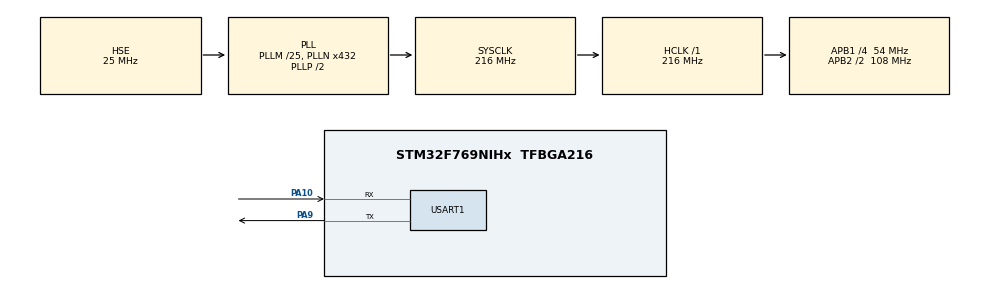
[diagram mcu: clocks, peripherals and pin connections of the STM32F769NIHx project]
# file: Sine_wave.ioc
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CORTEX_M7.ART_ACCELERATOR_ENABLE=0
CORTEX_M7.CPU_DCache=Enabled
CORTEX_M7.CPU_ICache=Enabled
Mcu.Family=STM32F7
Mcu.Name=STM32F769NIHx
Mcu.Package=TFBGA216
NVIC.PriorityGroup=NVIC_PRIORITYGROUP_4
PA10.Mode=Asynchronous
PA10.Signal=USART1_RX
PA13.Mode=Serial_Wire
PA13.Signal=SYS_JTMS-SWDIO
PA14.Mode=Serial_Wire
PA14.Signal=SYS_JTCK-SWCLK
PA9.Mode=Asynchronous
PA9.Signal=USART1_TX
PC14/OSC32_IN.Mode=LSE-External-Oscillator
PC14/OSC32_IN.Signal=RCC_OSC32_IN
PC15/OSC32_OUT.Mode=LSE-External-Oscillator
PC15/OSC32_OUT.Signal=RCC_OSC32_OUT
PH0/OSC_IN.Mode=HSE-External-Oscillator
PH0/OSC_IN.Signal=RCC_OSC_IN
PH1/OSC_OUT.Mode=HSE-External-Oscillator
PH1/OSC_OUT.Signal=RCC_OSC_OUT
ProjectManager.HeapSize=0x800
ProjectManager.StackSize=0x800
ProjectManager.TargetToolchain=STM32CubeIDE
RCC.AHBFreq_Value=216000000
RCC.APB1CLKDivider=RCC_HCLK_DIV4
RCC.APB1Freq_Value=54000000
RCC.APB1TimFreq_Value=108000000
RCC.APB2CLKDivider=RCC_HCLK_DIV2
RCC.APB2Freq_Value=108000000
RCC.APB2TimFreq_Value=216000000
RCC.CortexFreq_Value=216000000
RCC.HCLKFreq_Value=216000000
RCC.HSE_VALUE=25000000
RCC.HSI_VALUE=16000000
RCC.PLLM=25
RCC.PLLN=432
RCC.PLLQ=4
RCC.PLLSAIQ=3
RCC.PLLSourceVirtual=RCC_PLLSOURCE_HSE
RCC.SYSCLKFreq_VALUE=216000000
RCC.SYSCLKSource=RCC_SYSCLKSOURCE_PLLCLK
RCC.USBFreq_Value=108000000
RCC.VCOOutputFreq_Value=432000000
STMicroelectronics.X-CUBE-AI.9.0.0.ActivationBufferSizeList=128
STMicroelectronics.X-CUBE-AI.9.0.0.ActivationBuffers=pool0
STMicroelectronics.X-CUBE-AI.9.0.0.ActivationNames=pool0
STMicroelectronics.X-CUBE-AI.9.0.0.ActivationSizes=AI_SIN_WAVE_DATA_ACTIVATION_1_SIZE
STMicroelectronics.X-CUBE-AI.9.0.0.HeapSize=0x800
STMicroelectronics.X-CUBE-AI.9.0.0.InternalRamActivationBufferMaxSize=AI_SIN_WAVE_DATA_ACTIVATIONS_SIZE
STMicroelectronics.X-CUBE-AI.9.0.0.LatestDirectoryUsed-826814ab56f44155a73fceece242ecaec9d7efd1946fa1af281f79f9bccddd98=E\:\\AI_Workspace\\Machine_learning_Study
STMicroelectronics.X-CUBE-AI.9.0.0.MaximumNumberOfInputLayer=1
STMicroelectronics.X-CUBE-AI.9.0.0.MaximumNumberOfOutputLayer=1
STMicroelectronics.X-CUBE-AI.9.0.0.MaximumSizeOfInputLayer=1
STMicroelectronics.X-CUBE-AI.9.0.0.MaximumSizeOfOutputLayer=1
STMicroelectronics.X-CUBE-AI.9.0.0.ModelActualCompression-826814ab56f44155a73fceece242ecaec9d7efd1946fa1af281f79f9bccddd98=0.0
STMicroelectronics.X-CUBE-AI.9.0.0.ModelCompression-826814ab56f44155a73fceece242ecaec9d7efd1946fa1af281f79f9bccddd98=None
STMicroelectronics.X-CUBE-AI.9.0.0.ModelFlashOccupation-826814ab56f44155a73fceece242ecaec9d7efd1946fa1af281f79f9bccddd98=1284
STMicroelectronics.X-CUBE-AI.9.0.0.ModelHashList=826814ab56f44155a73fceece242ecaec9d7efd1946fa1af281f79f9bccddd98
STMicroelectronics.X-CUBE-AI.9.0.0.ModelKind-826814ab56f44155a73fceece242ecaec9d7efd1946fa1af281f79f9bccddd98=TFLITE
STMicroelectronics.X-CUBE-AI.9.0.0.ModelMacc-826814ab56f44155a73fceece242ecaec9d7efd1946fa1af281f79f9bccddd98=353
STMicroelectronics.X-CUBE-AI.9.0.0.ModelName-826814ab56f44155a73fceece242ecaec9d7efd1946fa1af281f79f9bccddd98=sin_wave
STMicroelectronics.X-CUBE-AI.9.0.0.ModelNameList=sin_wave
STMicroelectronics.X-CUBE-AI.9.0.0.ModelRamOccupation-826814ab56f44155a73fceece242ecaec9d7efd1946fa1af281f79f9bccddd98=128
STMicroelectronics.X-CUBE-AI.9.0.0.ModelStructureFile-826814ab56f44155a73fceece242ecaec9d7efd1946fa1af281f79f9bccddd98=E\:\\AI_Workspace\\Machine_learning_Study\\sine_model.tflite
STMicroelectronics.X-CUBE-AI.9.0.0.ModelType-826814ab56f44155a73fceece242ecaec9d7efd1946fa1af281f79f9bccddd98=STM32Cube.AI MCU runtime
STMicroelectronics.X-CUBE-AI.9.0.0.ReadyForCodeGeneration=true
STMicroelectronics.X-CUBE-AI.9.0.0.StackSize=0x800
STMicroelectronics.X-CUBE-AI.9.0.0.WorkingBufferStartAddrList=0xFFFFFFFF
STMicroelectronics.X-CUBE-AI.9.0.0.XAaCUBEAaAICcArtificialOoIntelligenceJjCore=true
STMicroelectronics.X-CUBE-AI.9.0.0.copyWeightToRam=false
STMicroelectronics.X-CUBE-AI.9.0.0.copyWeightToRam-826814ab56f44155a73fceece242ecaec9d7efd1946fa1af281f79f9bccddd98=false
STMicroelectronics.X-CUBE-AI.9.0.0.customLayerConfigEnabled=false
STMicroelectronics.X-CUBE-AI.9.0.0.customLayerConfigEnabled-826814ab56f44155a73fceece242ecaec9d7efd1946fa1af281f79f9bccddd98=false
STMicroelectronics.X-CUBE-AI.9.0.0.noOnnxIoTranspose=false
STMicroelectronics.X-CUBE-AI.9.0.0.noOnnxIoTranspose-826814ab56f44155a73fceece242ecaec9d7efd1946fa1af281f79f9bccddd98=false
STMicroelectronics.X-CUBE-AI.9.0.0.useInputAllocation=true
STMicroelectronics.X-CUBE-AI.9.0.0.useInputAllocation-826814ab56f44155a73fceece242ecaec9d7efd1946fa1af281f79f9bccddd98=true
STMicroelectronics.X-CUBE-AI.9.0.0.useOutputAllocation=true
STMicroelectronics.X-CUBE-AI.9.0.0.useOutputAllocation-826814ab56f44155a73fceece242ecaec9d7efd1946fa1af281f79f9bccddd98=true
USART1.VirtualMode-Asynchronous=VM_ASYNC
VP_STMicroelectronics.X-CUBE-AI_VS_ArtificialOoIntelligenceJjXAaCUBEAaAI_9.0.0.Mode=ArtificialOoIntelligenceJjXAaCUBEAaAI
board=STM32F769I-DISCO

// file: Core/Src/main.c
/* USER CODE BEGIN Header */
/**
 ******************************************************************************
 * @file           : main.c
 * @brief          : Main program body
 ******************************************************************************
 * @attention
 *
 * Copyright (c) 2024 STMicroelectronics.
 * All rights reserved.
 *
 * This software is licensed under terms that can be found in the LICENSE file
 * in the root directory of this software component.
 * If no LICENSE file comes with this software, it is provided AS-IS.
 *
 ******************************************************************************
 */
/* USER CODE END Header */
#include "main.h"
#include "usart.h"
#include "gpio.h"

/* USER CODE BEGIN Includes */
#include <stdio.h>
#include <stdlib.h>
#include <time.h>
#include <string.h>

#include "ai_datatypes_defines.h"
#include "ai_platform.h"
#include "sin_wave.h"
#include "sin_wave_data.h"
/* USER CODE END Includes */

/* USER CODE BEGIN PV */

/* @brief Statically allocated buffers.
 * Buffers can be dynamically allocated using malloc and size information
 * given by the report in ai_network_get_report().
 */
ai_u8 activations[AI_SIN_WAVE_DATA_ACTIVATIONS_SIZE];
ai_u8 in_data[AI_SIN_WAVE_IN_1_SIZE_BYTES];
ai_u8 out_data[AI_SIN_WAVE_OUT_1_SIZE_BYTES];

char TX_Buffer[128] = {0,};
int StrLen = 0;

/* AI buffer IO handlers */
ai_buffer *ai_input;
ai_buffer *ai_output;

float x_val = 3.0f;
float y_val = 0.0f;

/* USER CODE END PV */

void SystemClock_Config(void);

int main(void)
{

  /* Enable the CPU Cache */

  /* Enable I-Cache---------------------------------------------------------*/
  SCB_EnableICache();

  /* Enable D-Cache---------------------------------------------------------*/
  SCB_EnableDCache();

  /* MCU Configuration--------------------------------------------------------*/

  /* Reset of all peripherals, Initializes the Flash interface and the Systick. */
  HAL_Init();

  /* Configure the system clock */
  SystemClock_Config();

  /* Initialize all configured peripherals */
  MX_GPIO_Init();
  MX_USART1_UART_Init();
  /* USER CODE BEGIN 2 */

	ai_handle network = AI_HANDLE_NULL;
	ai_error err;
	ai_network_report report;

	/** @brief Initialize network */
	const ai_handle acts[] = { activations };
	err = ai_sin_wave_create_and_init(&network, acts, NULL);
	if (err.type != AI_ERROR_NONE)
	{
		StrLen = sprintf(TX_Buffer, "ai init_and_create error\r\n");
		HAL_UART_Transmit(&huart1, TX_Buffer, StrLen, 1000);
		return -1;
	}

	/** @brief {optional} for debug/log purpose */
	if (ai_sin_wave_get_report(network, &report) != true)
	{
		StrLen = sprintf(TX_Buffer, "ai get report error\r\n");
		HAL_UART_Transmit(&huart1, TX_Buffer, StrLen, 1000);
		return -1;
	}

	StrLen = sprintf(TX_Buffer, "Model name      : %s\r\n", report.model_name);
	HAL_UART_Transmit(&huart1, TX_Buffer, StrLen, 1000);
	StrLen = sprintf(TX_Buffer, "Model signature : %s\r\n", report.model_signature);
	HAL_UART_Transmit(&huart1, TX_Buffer, StrLen, 1000);

	ai_input = &report.inputs[0];
	ai_output = &report.outputs[0];

	StrLen = sprintf(TX_Buffer,
			"input[0] : (%d, %d, %d)\r\n",
			(int) AI_BUFFER_SHAPE_ELEM(ai_input, AI_SHAPE_HEIGHT),
			(int) AI_BUFFER_SHAPE_ELEM(ai_input, AI_SHAPE_WIDTH),
			(int) AI_BUFFER_SHAPE_ELEM(ai_input, AI_SHAPE_CHANNEL));
	HAL_UART_Transmit(&huart1, TX_Buffer, StrLen, 1000);

	StrLen = sprintf(TX_Buffer,
			"output[0] : (%d, %d, %d)\r\n",
			(int) AI_BUFFER_SHAPE_ELEM(ai_output, AI_SHAPE_HEIGHT),
			(int) AI_BUFFER_SHAPE_ELEM(ai_output, AI_SHAPE_WIDTH),
			(int) AI_BUFFER_SHAPE_ELEM(ai_output, AI_SHAPE_CHANNEL));
	HAL_UART_Transmit(&huart1, TX_Buffer, StrLen, 1000);

	/** @brief Fill input buffer with random values */
	for (uint32_t i = 0; i < AI_SIN_WAVE_IN_1_SIZE; i++)
	{
		((ai_float*) in_data)[i] = (ai_float) x_val;
	}

	/** @brief Normalize, convert and/or quantize inputs if necessary... */

	/** @brief Perform inference */
	ai_i32 n_batch;

	/** @brief Create the AI buffer IO handlers
	 *  @note  ai_inuput/ai_output are already initilaized after the
	 *         ai_network_get_report() call. This is just here to illustrate
	 *         the case where get_report() is not called.
	 */
	ai_input = ai_sin_wave_inputs_get(network, NULL);
	ai_output = ai_sin_wave_outputs_get(network, NULL);

	/** @brief Set input/output buffer addresses */
	ai_input[0].data = AI_HANDLE_PTR(in_data);
	ai_output[0].data = AI_HANDLE_PTR(out_data);

  /* USER CODE END 2 */

  /* Infinite loop */
	while (1)
	{

    /* USER CODE BEGIN 3 */

		for (uint32_t i = 0; i < AI_SIN_WAVE_IN_1_SIZE; i++)
		{
			((ai_float*) in_data)[i] = (ai_float) x_val;
		}

		/** @brief Perform the inference */
		n_batch = ai_sin_wave_run(network, &ai_input[0], &ai_output[0]);
		if (n_batch != 1)
		{
			err = ai_sin_wave_get_error(network);
			StrLen = sprintf(TX_Buffer, "ai run error %d, %d\r\n", err.type, err.code);
			HAL_UART_Transmit(&huart1, TX_Buffer, StrLen, 1000);
			return -1;
		}

		/** @brief Post-process the output results/predictions */
		y_val = ((float*) out_data)[0];

		StrLen = sprintf(TX_Buffer, "Input Data : %.5f", x_val);
		HAL_UART_Transmit(&huart1, TX_Buffer, StrLen, 1000);
		StrLen = sprintf(TX_Buffer, "|   Output Data : %.5f\r\n", y_val);
		HAL_UART_Transmit(&huart1, TX_Buffer, StrLen, 1000);

		if (x_val > 6.0f)
		{
			x_val = 0.0f;
		}
		else
		{
			x_val = x_val + 0.1f;
		}

		HAL_Delay(500);
	}
  /* USER CODE END 3 */
}

void SystemClock_Config(void)
{
  RCC_OscInitTypeDef RCC_OscInitStruct = {0};
  RCC_ClkInitTypeDef RCC_ClkInitStruct = {0};

  /** Configure LSE Drive Capability
  */
  HAL_PWR_EnableBkUpAccess();

  /** Configure the main internal regulator output voltage
  */
  __HAL_RCC_PWR_CLK_ENABLE();
  __HAL_PWR_VOLTAGESCALING_CONFIG(PWR_REGULATOR_VOLTAGE_SCALE1);

  /** Initializes the RCC Oscillators according to the specified parameters
  * in the RCC_OscInitTypeDef structure.
  */
  RCC_OscInitStruct.OscillatorType = RCC_OSCILLATORTYPE_HSE;
  RCC_OscInitStruct.HSEState = RCC_HSE_ON;
  RCC_OscInitStruct.PLL.PLLState = RCC_PLL_ON;
  RCC_OscInitStruct.PLL.PLLSource = RCC_PLLSOURCE_HSE;
  RCC_OscInitStruct.PLL.PLLM = 25;
  RCC_OscInitStruct.PLL.PLLN = 432;
  RCC_OscInitStruct.PLL.PLLP = RCC_PLLP_DIV2;
  RCC_OscInitStruct.PLL.PLLQ = 4;
  RCC_OscInitStruct.PLL.PLLR = 2;
  if (HAL_RCC_OscConfig(&RCC_OscInitStruct) != HAL_OK)
  {
    Error_Handler();
  }

  /** Activate the Over-Drive mode
  */
  if (HAL_PWREx_EnableOverDrive() != HAL_OK)
  {
    Error_Handler();
  }

  /** Initializes the CPU, AHB and APB buses clocks
  */
  RCC_ClkInitStruct.ClockType = RCC_CLOCKTYPE_HCLK|RCC_CLOCKTYPE_SYSCLK
                              |RCC_CLOCKTYPE_PCLK1|RCC_CLOCKTYPE_PCLK2;
  RCC_ClkInitStruct.SYSCLKSource = RCC_SYSCLKSOURCE_PLLCLK;
  RCC_ClkInitStruct.AHBCLKDivider = RCC_SYSCLK_DIV1;
  RCC_ClkInitStruct.APB1CLKDivider = RCC_HCLK_DIV4;
  RCC_ClkInitStruct.APB2CLKDivider = RCC_HCLK_DIV2;

  if (HAL_RCC_ClockConfig(&RCC_ClkInitStruct, FLASH_LATENCY_7) != HAL_OK)
  {
    Error_Handler();
  }
}

void Error_Handler(void)
{
	__disable_irq();
	while (1)
	{
	}
}
